AUTOSAR XML (schema 00049)
package /AppDesign
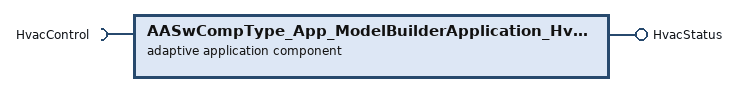
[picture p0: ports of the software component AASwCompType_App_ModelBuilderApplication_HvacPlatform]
  adaptive application sw component type AASwCompType_App_ModelBuilderApplication_HvacPlatform
    provide port HvacStatus: provided-interface=HvacStatus
    require port HvacControl: required-interface=HvacControl
  executable HvacPlatform: category=APPLICATION_LEVEL, version=1.0.0
    root sw component prototype RootSwcPrototype: application-type=AASwCompType_App_ModelBuilderApplication_HvacPlatform
  process design PrcDesign_App_ModelBuilderApplication_HvacPlatform: executable=HvacPlatform
  software cluster design SwClDesign_App_ModelBuilderApplication: contained-process=PrcDesign_App_ModelBuilderApplication_HvacPlatform
